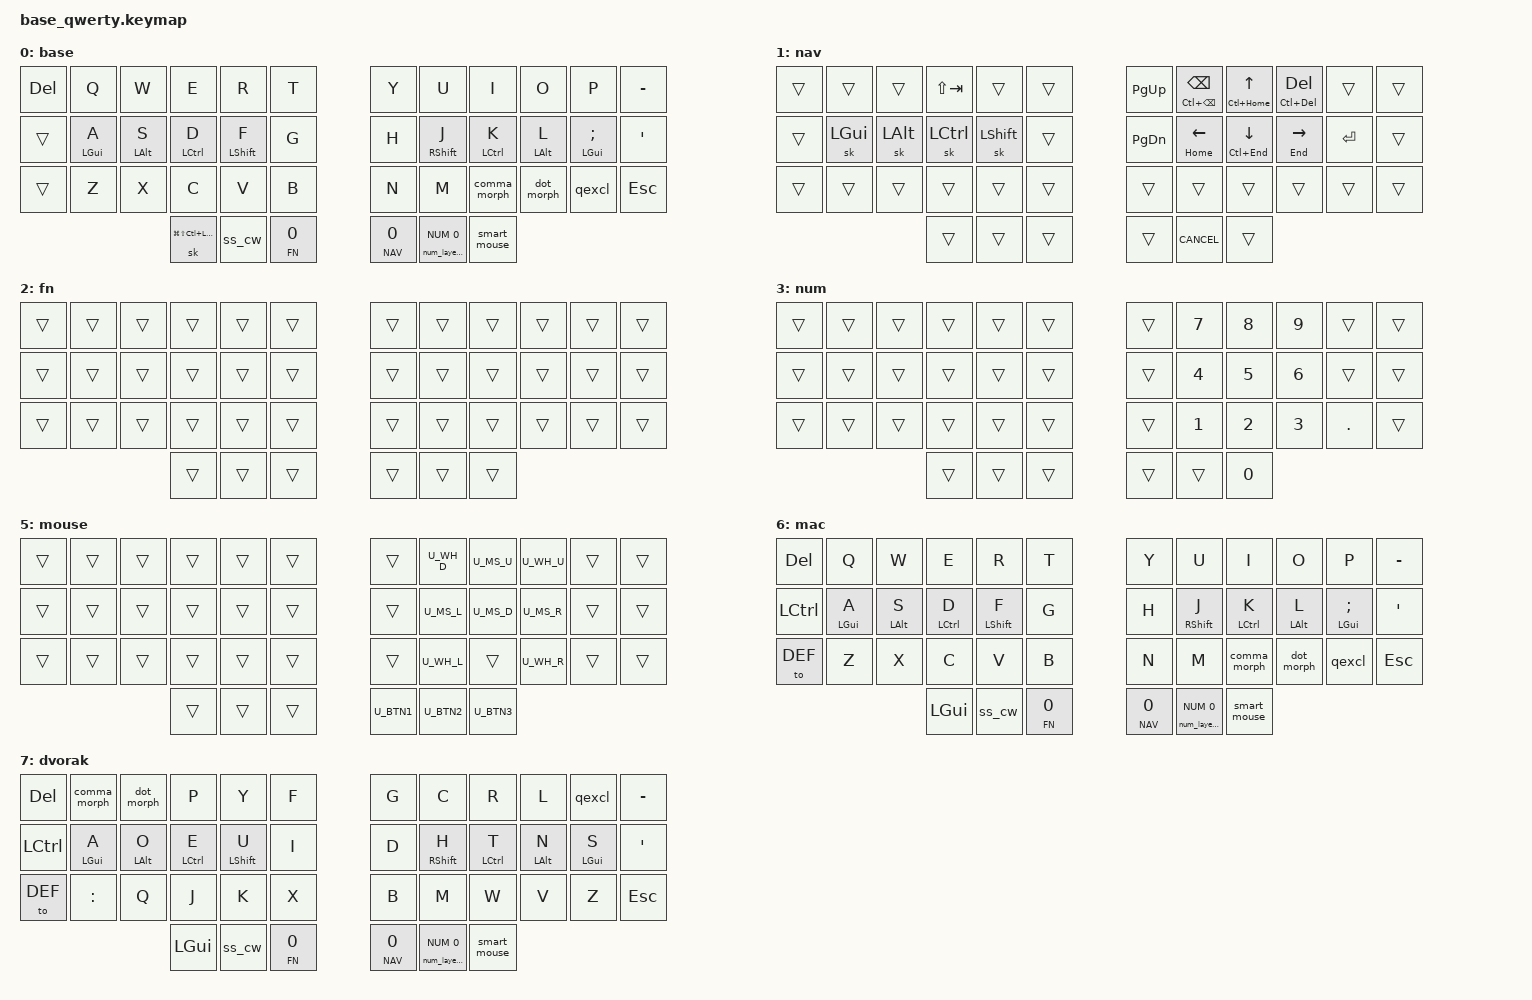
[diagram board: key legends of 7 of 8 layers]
#include <behaviors.dtsi>
#include <dt-bindings/zmk/keys.h>
#if CONFIG_WIRELESS
    #include <dt-bindings/zmk/bt.h>
    #define _BT_SEL_KEYS_ &bt BT_SEL 0 &bt BT_SEL 1 &bt BT_SEL 2 &bt BT_SEL 3 &bt BT_CLR
#else
    #define _BT_SEL_KEYS_ &trans &trans &trans &trans &trans
#endif

#include "node-free/helper.h"
#include "node-free/keypos_42keys.h"

#define DEF    0
#define NAV    1
#define FN     2
#define NUM    3
#define SYS    4
#define MOUSE  5
#define MAC    6
#define DVORAK 7

#include "combos.dtsi"
#include "mouse.dtsi"

ZMK_CONDITIONAL_LAYER(FN NUM, SYS)  // FN + NUM --> SYS

/* Navigation keys and misc shortcuts */

&mt {
    flavor = "tap-preferred";
    tapping-term-ms = <220>;
    quick-tap-ms = <220>;                // repeat on tap-into-hold
    hold-trigger-key-positions = <0>;    // tap on interrupt
};

#define NAV_LEFT    &mt HOME        LEFT    // tap: left  | long-tap: beginning of line
#define NAV_RIGHT   &mt END         RIGHT   // tap: right | long-tap: end       of line
#define NAV_UP      &mt LC(HOME)    UP      // tap: up    | long-tap: beginning of document
#define NAV_DOWN    &mt LC(END)     DOWN    // tap: down  | long-tap: end       of document
#define NAV_BSPC    &mt LC(BSPC)    BSPC    // tap: bspc  | long-tap: delete word backward
#define NAV_DEL     &mt LC(DEL)     DEL     // tap: del   | long-tap: delete word forward

#define XXX &none
#define ___ &trans

#define CANCEL      &kp K_CANCEL            // cancel caps-word, num-word, and smart mouse
#define HYPER       &sk LG(LS(LC(LALT)))

/* Settings */

#define QUICK_TAP_MS 175

&sk {   // sticky-key config
    release-after-ms = <600>;       // release after 0.6s
    quick-release;                  // no double capitalization when rolling keys
};

&sl {   // sticky-layer config
    ignore-modifiers;
};

&lt {   // layer-tap config
    flavor = "balanced";
    tapping-term-ms = <200>;
    quick-tap-ms = <QUICK_TAP_MS>;
};

&caps_word {    // mods deactivate caps-word, requires PR #1441
    /delete-property/ ignore-modifiers;
};

&num_word { // num-word, requires PR #1441
    layers = <NUM>;
};

/* Homerow mods */

#define KEYS_L LT0 LT1 LT2 LT3 LT4 LM0 LM1 LM2 LM3 LM4 LB0 LB1 LB2 LB3 LB4  // Left hand side
#define KEYS_R RT0 RT1 RT2 RT3 RT4 RM0 RM1 RM2 RM3 RM4 RB0 RB1 RB2 RB3 RB4  // Right hand side
#define THUMBS LH2 LH1 LH0 RH0 RH1 RH2

ZMK_BEHAVIOR(hml, hold_tap, // left-hand HRMs
    flavor = "balanced";
    tapping-term-ms = <280>;
    quick-tap-ms = <QUICK_TAP_MS>;
    global-quick-tap-ms = <150>;        // requires PR #1387
    bindings = <&kp>, <&kp>;
    hold-trigger-key-positions = <KEYS_R THUMBS>;
    hold-trigger-on-release;            // requires PR #1423
)

ZMK_BEHAVIOR(hmr, hold_tap, // right-hand HRMs
    flavor = "balanced";
    tapping-term-ms = <280>;
    quick-tap-ms = <QUICK_TAP_MS>;
    global-quick-tap-ms = <150>;
    bindings = <&kp>, <&kp>;
    hold-trigger-key-positions = <KEYS_L THUMBS>;
    hold-trigger-on-release;
)

/* Custom Behaviors */

// tap: num-word | double-tap: sticky num-layer | hold: num-layer
ZMK_BEHAVIOR(num_dance, tap_dance,
    tapping-term-ms = <200>;
    bindings = <&num_word>, <&sl NUM>;
)
ZMK_BEHAVIOR(num_layer_word, hold_tap,
    flavor = "balanced";
    tapping-term-ms = <200>;
    quick-tap-ms = <QUICK_TAP_MS>;
    bindings = <&mo>, <&num_dance>;
)
#define NUM_WORD &num_layer_word NUM 0

// Mouse layer that deactivates automatically on all other keys, requires PR #1366
ZMK_BEHAVIOR(smart_mouse, tri_state,
    bindings = <&tog MOUSE>, <&none>, <&tog MOUSE>;
    ignored-key-positions = <RT1 RT2 RT3 RM1 RM2 RM3 RB1 RB3 RH0 RH1 RH2>;  // Mouse keys
    ignored-layers = <MOUSE>;
)

// tap: sticky-shift | shift + tap/double-tap: caps-word | hold: shift
ZMK_BEHAVIOR(ss_cw, mod_morph,
    bindings = <&sk LSHFT>, <&caps_word>;
    mods = <(MOD_LSFT)>;
)

// tap: backspace | lshft + tap: delete | rshft + tap: shift-delete | hold: fn layer
ZMK_BEHAVIOR(bs_del, mod_morph,
    bindings = <&kp BSPC>, <&kp DEL>;
    mods = <(MOD_LSFT|MOD_RSFT)>;
    keep-mods = <MOD_LSFT>;
)
ZMK_BEHAVIOR(lt_bspc, hold_tap,
    flavor = "balanced";
    tapping-term-ms = <200>;
    quick-tap-ms = <QUICK_TAP_MS>;
    bindings = <&mo>, <&bs_del>;
)

// tap: space | shift + tap: dot -> space -> sticky shift | hold: activate layer
ZMK_BEHAVIOR(dot_spc, macro,
    wait-ms = <0>;
    tap-ms = <5>;
    bindings = <&kp DOT &kp SPACE &sk LSHFT>;
)
ZMK_BEHAVIOR(spc_morph, mod_morph,
    bindings = <&kp SPACE>, <&dot_spc>;
    mods = <(MOD_LSFT|MOD_RSFT)>;
)
ZMK_BEHAVIOR(lt_spc, hold_tap,
    flavor = "balanced";
    tapping-term-ms = <QUICK_TAP_MS>;
    bindings = <&sl>, <&spc_morph>;
)

// tap: comma | shift + tap: semicolon | ctrl + shift + tap: <
ZMK_BEHAVIOR(comma_inner_morph, mod_morph,
    bindings = <&kp SEMICOLON>, <&kp LESS_THAN>;
    mods = <(MOD_LCTL|MOD_RCTL)>;
)
ZMK_BEHAVIOR(comma_morph, mod_morph,
    mods = <(MOD_LSFT|MOD_RSFT)>;
    bindings = <&kp COMMA>, <&comma_inner_morph>;
)

// tap: dot | shift + tap: colon | ctrl + shift + tap: >
ZMK_BEHAVIOR(dot_inner_morph, mod_morph,
    bindings = <&kp COLON>, <&kp GREATER_THAN>;
    mods = <(MOD_LCTL|MOD_RCTL)>;
)
ZMK_BEHAVIOR(dot_morph, mod_morph,
    bindings = <&kp DOT>, <&dot_inner_morph>;
    mods = <(MOD_LSFT|MOD_RSFT)>;
)

// tap: qmark | shift + tap: excl
ZMK_BEHAVIOR(qexcl, mod_morph,
    bindings = <&kp QMARK>, <&kp EXCL>;
    mods = <(MOD_LSFT|MOD_RSFT)>;
)

// Alt+Tab swapper, requires PR #1366
/*ZMK_BEHAVIOR(swap, tri-state,
    bindings = <&kt LALT>, <&kp TAB>, <&kt LALT>;
    ignored-key-positions = <LT2>;
)*/

/* Keymap */

ZMK_LAYER(base, // 0
//╭─────────────┬─────────────┬─────────────┬─────────────┬─────────────┬─────────────╮ ╭─────────────┬─────────────┬─────────────┬─────────────┬─────────────┬─────────────╮
    &kp DEL       &kp Q         &kp W         &kp E         &kp R         &kp T           &kp Y         &kp U         &kp I         &kp O         &kp P         &kp MINUS
//├─────────────┼─────────────┼─────────────┼─────────────┼─────────────┼─────────────┤ ├─────────────┼─────────────┼─────────────┼─────────────┼─────────────┴─────────────┤
    ___           &hml LGUI A   &hml LALT S   &hml LCTRL D  &hml LSHFT F  &kp G           &kp H         &hmr RSHFT J  &hmr LCTRL K  &hmr LALT L  &hmr LGUI SEMI &kp SQT
//├─────────────┼─────────────┼─────────────┼─────────────┼─────────────┼─────────────┤ ├─────────────┼─────────────┼─────────────┼─────────────┼─────────────┴─────────────┤
    ___           &kp Z         &kp X         &kp C         &kp V         &kp B           &kp N         &kp M         &comma_morph  &dot_morph    &qexcl        &kp ESC
//╰─────────────┴─────────────┴─────────────┼─────────────┼─────────────┼─────────────┤ ├─────────────┼─────────────┼─────────────┼─────────────┴─────────────┴─────────────╯
                                              HYPER         &ss_cw        &lt_bspc FN 0   &lt_spc NAV 0 NUM_WORD      &smart_mouse
//                                          ╰─────────────┴─────────────┴─────────────╯ ╰─────────────┴─────────────┴─────────────╯
)

ZMK_LAYER(nav,
//╭─────────────┬─────────────┬─────────────┬─────────────┬─────────────┬─────────────╮ ╭─────────────┬─────────────┬─────────────┬─────────────┬─────────────┬─────────────╮
    ___           ___           ___           &kp LS(TAB)   ___           ___             &kp PG_UP     NAV_BSPC      NAV_UP        NAV_DEL       ___           ___
//├─────────────┼─────────────┼─────────────┼─────────────┼─────────────┼─────────────┤ ├─────────────┼─────────────┼─────────────┼─────────────┼─────────────┴─────────────┤
    ___           &sk LGUI      &sk LALT      &sk LCTRL     &sk LSHFT     ___             &kp PG_DN     NAV_LEFT      NAV_DOWN      NAV_RIGHT     &kp RET       ___
//├─────────────┼─────────────┼─────────────┼─────────────┼─────────────┼─────────────┤ ├─────────────┼─────────────┼─────────────┼─────────────┼─────────────┴─────────────┤
    ___           ___           ___           ___           ___           ___             ___           ___           ___           ___           ___           ___
//╰─────────────┴─────────────┴─────────────┼─────────────┼─────────────┼─────────────┤ ├─────────────┼─────────────┼─────────────┼─────────────┴─────────────┴─────────────╯
                                              ___           ___           ___             ___           CANCEL        ___
//                                          ╰─────────────┴─────────────┴─────────────╯ ╰─────────────┴─────────────┴─────────────╯
)

ZMK_LAYER(fn,   // 2
//╭─────────────┬─────────────┬─────────────┬─────────────┬─────────────┬─────────────╮ ╭─────────────┬─────────────┬─────────────┬─────────────┬─────────────┬─────────────╮
    ___           ___           ___           ___           ___           ___             ___           ___           ___           ___           ___           ___
//├─────────────┼─────────────┼─────────────┼─────────────┼─────────────┼─────────────┤ ├─────────────┼─────────────┼─────────────┼─────────────┼─────────────┴─────────────┤
    ___           ___           ___           ___           ___           ___             ___           ___           ___           ___           ___           ___
//├─────────────┼─────────────┼─────────────┼─────────────┼─────────────┼─────────────┤ ├─────────────┼─────────────┼─────────────┼─────────────┼─────────────┴─────────────┤
    ___           ___           ___           ___           ___           ___             ___           ___           ___           ___           ___           ___
//╰─────────────┴─────────────┴─────────────┼─────────────┼─────────────┼─────────────┤ ├─────────────┼─────────────┼─────────────┼─────────────┴─────────────┴─────────────╯
                                              ___           ___           ___             ___           ___           ___
//                                          ╰─────────────┴─────────────┴─────────────╯ ╰─────────────┴─────────────┴─────────────╯
)

ZMK_LAYER(num,    // 3
//╭─────────────┬─────────────┬─────────────┬─────────────┬─────────────┬─────────────╮ ╭─────────────┬─────────────┬─────────────┬─────────────┬─────────────┬─────────────╮
    ___           ___           ___           ___           ___           ___             ___           &kp N7        &kp N8        &kp N9        ___           ___
//├─────────────┼─────────────┼─────────────┼─────────────┼─────────────┼─────────────┤ ├─────────────┼─────────────┼─────────────┼─────────────┼─────────────┴─────────────┤
    ___           ___           ___           ___           ___           ___             ___           &kp N4        &kp N5        &kp N6        ___           ___
//├─────────────┼─────────────┼─────────────┼─────────────┼─────────────┼─────────────┤ ├─────────────┼─────────────┼─────────────┼─────────────┼─────────────┴─────────────┤
    ___           ___           ___           ___           ___           ___             ___           &kp N1        &kp N2        &kp N3        &kp DOT       ___
//╰─────────────┴─────────────┴─────────────┼─────────────┼─────────────┼─────────────┤ ├─────────────┼─────────────┼─────────────┼─────────────┴─────────────┴─────────────╯
                                              ___           ___           ___             ___           ___           &kp N0
//                                          ╰─────────────┴─────────────┴─────────────╯ ╰─────────────┴─────────────┴─────────────╯
)

ZMK_LAYER(sys,    // 4
//╭─────────────┬─────────────┬─────────────┬─────────────┬─────────────┬─────────────╮ ╭─────────────┬─────────────┬─────────────┬─────────────┬─────────────┬─────────────╮
    ___                                      _BT_SEL_KEYS_                                ___           ___           ___           ___           ___           ___
//├─────────────┼─────────────┼─────────────┼─────────────┼─────────────┼─────────────┤ ├─────────────┼─────────────┼─────────────┼─────────────┼─────────────┴─────────────┤
    ___           ___           ___           ___           ___           ___             ___           ___           ___           ___           ___           ___
//├─────────────┼─────────────┼─────────────┼─────────────┼─────────────┼─────────────┤ ├─────────────┼─────────────┼─────────────┼─────────────┼─────────────┴─────────────┤
    ___           ___           ___           ___           ___           ___             ___           ___           ___           ___           ___           ___
//╰─────────────┴─────────────┴─────────────┼─────────────┼─────────────┼─────────────┤ ├─────────────┼─────────────┼─────────────┼─────────────┴─────────────┴─────────────╯
                                              ___           ___           ___             ___           ___           ___
//                                          ╰─────────────┴─────────────┴─────────────╯ ╰─────────────┴─────────────┴─────────────╯
)

ZMK_LAYER(mouse,    // 5
//╭─────────────┬─────────────┬─────────────┬─────────────┬─────────────┬─────────────╮ ╭─────────────┬─────────────┬─────────────┬─────────────┬─────────────┬─────────────╮
    ___           ___           ___           ___           ___           ___             ___           U_WH_D        U_MS_U        U_WH_U        ___           ___
//├─────────────┼─────────────┼─────────────┼─────────────┼─────────────┼─────────────┤ ├─────────────┼─────────────┼─────────────┼─────────────┼─────────────┴─────────────┤
    ___           ___           ___           ___           ___           ___             ___           U_MS_L        U_MS_D        U_MS_R        ___           ___
//├─────────────┼─────────────┼─────────────┼─────────────┼─────────────┼─────────────┤ ├─────────────┼─────────────┼─────────────┼─────────────┼─────────────┴─────────────┤
    ___           ___           ___           ___           ___           ___             ___           U_WH_L        ___           U_WH_R        ___           ___
//╰─────────────┴─────────────┴─────────────┼─────────────┼─────────────┼─────────────┤ ├─────────────┼─────────────┼─────────────┼─────────────┴─────────────┴─────────────╯
                                              ___           ___           ___             U_BTN1        U_BTN2        U_BTN3
//                                          ╰─────────────┴─────────────┴─────────────╯ ╰─────────────┴─────────────┴─────────────╯
)

ZMK_LAYER(mac,    // 6
//╭─────────────┬─────────────┬─────────────┬─────────────┬─────────────┬─────────────╮ ╭─────────────┬─────────────┬─────────────┬─────────────┬─────────────┬─────────────╮
    &kp DEL       &kp Q         &kp W         &kp E         &kp R         &kp T           &kp Y         &kp U         &kp I         &kp O         &kp P         &kp MINUS
//├─────────────┼─────────────┼─────────────┼─────────────┼─────────────┼─────────────┤ ├─────────────┼─────────────┼─────────────┼─────────────┼─────────────┴─────────────┤
    &kp LCTRL     &hml LGUI A   &hml LALT S   &hml LCTRL D  &hml LSHFT F  &kp G           &kp H         &hmr RSHFT J  &hmr LCTRL K  &hmr LALT L  &hmr LGUI SEMI &kp SQT
//├─────────────┼─────────────┼─────────────┼─────────────┼─────────────┼─────────────┤ ├─────────────┼─────────────┼─────────────┼─────────────┼─────────────┴─────────────┤
    &to DEF       &kp Z         &kp X         &kp C         &kp V         &kp B           &kp N         &kp M         &comma_morph  &dot_morph    &qexcl        &kp ESC
//╰─────────────┴─────────────┴─────────────┼─────────────┼─────────────┼─────────────┤ ├─────────────┼─────────────┼─────────────┼─────────────┴─────────────┴─────────────╯
                                              &kp LGUI      &ss_cw        &lt_bspc FN 0   &lt_spc NAV 0 NUM_WORD      &smart_mouse
//                                          ╰─────────────┴─────────────┴─────────────╯ ╰─────────────┴─────────────┴─────────────╯
)

ZMK_LAYER(dvorak,    // 7
//╭─────────────┬─────────────┬─────────────┬─────────────┬─────────────┬─────────────╮ ╭─────────────┬─────────────┬─────────────┬─────────────┬─────────────┬─────────────╮
    &kp DEL       &comma_morph  &dot_morph    &kp P         &kp Y         &kp F           &kp G         &kp C         &kp R         &kp L         &qexcl        &kp MINUS
//├─────────────┼─────────────┼─────────────┼─────────────┼─────────────┼─────────────┤ ├─────────────┼─────────────┼─────────────┼─────────────┼─────────────┴─────────────┤
    &kp LCTRL     &hml LGUI A   &hml LALT O   &hml LCTRL E  &hml LSHFT U  &kp I           &kp D         &hmr RSHFT H  &hmr LCTRL T  &hmr LALT N   &hmr LGUI S   &kp SQT
//├─────────────┼─────────────┼─────────────┼─────────────┼─────────────┼─────────────┤ ├─────────────┼─────────────┼─────────────┼─────────────┼─────────────┴─────────────┤
    &to DEF       &kp COLON     &kp Q         &kp J         &kp K         &kp X           &kp B         &kp M         &kp W         &kp V         &kp Z         &kp ESC
//╰─────────────┴─────────────┴─────────────┼─────────────┼─────────────┼─────────────┤ ├─────────────┼─────────────┼─────────────┼─────────────┴─────────────┴─────────────╯
                                              &kp LGUI      &ss_cw        &lt_bspc FN 0   &lt_spc NAV 0 NUM_WORD      &smart_mouse
//                                          ╰─────────────┴─────────────┴─────────────╯ ╰─────────────┴─────────────┴─────────────╯
)
